# MEC1703 register map
Vendor: Microchip Technology; Series: MEC1703; File version: 0
CPU: CM4 r1p0, little endian, MPU, FPU, 3 interrupt priority bits
Registers are 32-bit, read-write, reset 0x0 unless marked. A register's access mark holds for its fields unless they carry their own. Offsets are from the block's base; [hi:lo] are bit positions; {n}, {i} and the like mark numbered series.

## EEPROM — This block is the 2K x 8bit EEPROM.
Base 0x40002C00; register names take the prefix EEPROM_
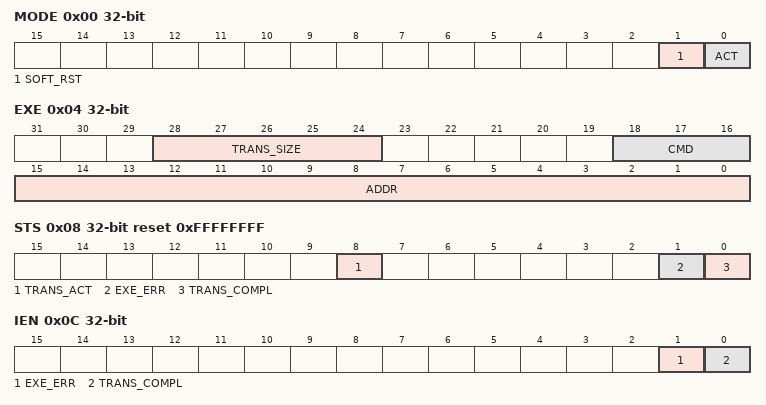
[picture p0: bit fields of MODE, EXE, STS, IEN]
0x00 MODE — EEPROM Mode Register
  [1] SOFT_RST — This write-only bit is used to reset the EEPROM
  [0] ACT — This bit is used to enable and disable the EEPROM controller.
0x04 EXE — EEPROM Execute Register
  [28:24] TRANS_SIZE — The number of bytes to be transferred between the EEPROM fabric and the buffer. A count of 0 is means a transfer of 32 bytes. This field is only applicable for WRITE and READ commands.
  [18:16] CMD — A write to this register automatically starts an EEPROM transfer between the fabric and the buffer. 3=WRITE STATUS; 2=READ STATUS; 1=WRITE; 0=READ.
  [15:0] ADDR — This register represents a byte address in the EEPROM. Bits[15:11] should be 0, but there is error flagged if they are not. This field only applies to READ and WRITE commands. It does not apply to READ STATUS and WRITE STATUS commands.
0x08 STS reset 0xFFFFFFFF — EEPROM Status Register
  [8] TRANS_ACT — A transfer between the EEPROM fabric and the EEPROM Buffer Register is in progress.
  [1] EXE_ERR — This bit is set to '1b' if an illegal command has been programmed into the block. (R/WC) A command is illegal if: The EEPROM Execute Register is written while a previous command has not yet completed (that is, while TRANSFER_ACTIVE is '1b'); An illegal value was written into the COMMAND field.
  [0] TRANS_COMPL — This bit indicated whether the transfer between the EEPROM fabric and the EEPROM Buffer Register has completed. (R/WC) 1=The transfer between the EEPROM fabric and the EEPROM Buffer Register has completed. 0=The transfer between the EEPROM fabric and the EEPROM Buffer Register has not yet completed.
0x0C IEN — EEPROM Interrupt Enable Register
  [1] EXE_ERR — Assert an EEPROM interrupt when the EXECUTION_ERROR status is asserted. 1=Enable Interrupt; 0=Disable Interrupt.
  [0] TRANS_COMPL — Assert an EEPROM interrupt when the TRANSFER_COMPLETE status is asserted. 1=Enable Interrupt; 0=Disable Interrupt.
0x10 PSWD — EEPROM Password Register
  [30:0] PSWD — If this 31-bit value matches the key in the EEPROM Unlock Register then the EEPROM array can be read or written. This register is write-once only. Once written, it can be neither read nor written until the next system reset.
0x14 UNLOCK — EEPROM Unlock Register
  [30:0] UNLOCK — When this 31-bit register is written, the least significant 31 bits of the write are compared to the. EEPROM Password Register that stores the key. If all bits match, the LOCK bit in the EEPROM Status Register cleared, and the EEPROM array can be read or written. This register is write only.
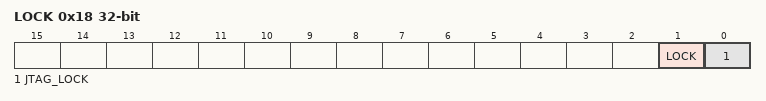
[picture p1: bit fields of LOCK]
0x18 LOCK — EEPROM Lock Register
  [1] LOCK — EEPROM Access Lock. When this bit is set to '1b', the EEPROM is locked from all accesses, including reads, writes and status queries. Once set to '1b' it can only be cleared to '0b' by a RESET_SYS or by writing the EEPROM Unlock. Register with a value that matches the contents of the EEPROM Password Register. 1=EEPROM is locked and cannot be accessed. 0=EEPROM is unlocked and may be accessed
  [0] JTAG_LOCK — If this bit is set to '1b' the LOCK bit is set to '1b' whenever the JTAG/SWD test interface is activated. This has priority over the EEPROM Unlock Register register, so that writing the EEPROM Unlock Register register with a value that matches the EEPROM Password Register if JTAG/SWD is active at the time. 1=The LOCK bit is set to '1b' whenever the JTAG/SWD test interface is activated. 0=The JTAG/SWD test interface has no effect on the LOCK bit.
{0x20+4i} EEBUF_u32[{i}] (i=0..7) — One byte of EEPROM Buffer Register. The Data buffer of 32 bytes is used to transfer data to and from the EEPROM fabric. For WRITES, it must be written before the WRITE command is started. For READ STATUS and WRITE STATUS commands, only the first byte (offset 0 in this register) is used.
{0x20+2i} EEBUF_u16[{i}] (i=0..15) 16-bit — One byte of EEPROM Buffer Register. The Data buffer of 32 bytes is used to transfer data to and from the EEPROM fabric. For WRITES, it must be written before the WRITE command is started. For READ STATUS and WRITE STATUS commands, only the first byte (offset 0 in this register) is used.
{0x20+i} EEBUF_u08[{i}] (i=0..31) 8-bit — One byte of EEPROM Buffer Register. The Data buffer of 32 bytes is used to transfer data to and from the EEPROM fabric. For WRITES, it must be written before the WRITE command is started. For READ STATUS and WRITE STATUS commands, only the first byte (offset 0 in this register) is used.
